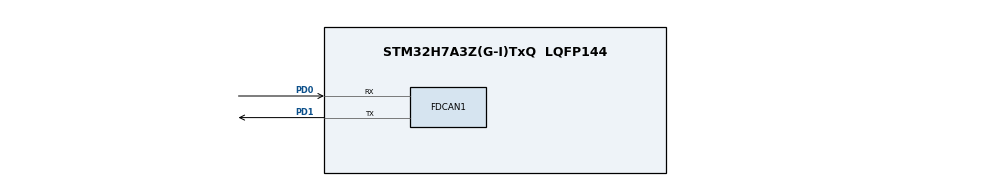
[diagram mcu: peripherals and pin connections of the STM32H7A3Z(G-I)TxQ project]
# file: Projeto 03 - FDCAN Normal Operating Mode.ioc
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FDCAN1.AutoRetransmission=ENABLE
FDCAN1.DataPrescaler=2
FDCAN1.DataSyncJumpWidth=12
FDCAN1.DataTimeSeg1=12
FDCAN1.DataTimeSeg2=12
FDCAN1.FrameFormat=FDCAN_FRAME_FD_BRS
FDCAN1.NominalSyncJumpWidth=13
FDCAN1.NominalTimeSeg1=86
FDCAN1.NominalTimeSeg2=13
FDCAN1.RxBufferSize=FDCAN_DATA_BYTES_12
FDCAN1.RxBuffersNbr=1
FDCAN1.StdFiltersNbr=1
FDCAN1.TxBuffersNbr=1
FDCAN1.TxElmtSize=FDCAN_DATA_BYTES_12
Mcu.Family=STM32H7
Mcu.Name=STM32H7A3Z(G-I)TxQ
Mcu.Package=LQFP144
NVIC.PriorityGroup=NVIC_PRIORITYGROUP_4
PD0.Mode=FDCAN_Activate
PD0.Signal=FDCAN1_RX
PD1.Mode=FDCAN_Activate
PD1.Signal=FDCAN1_TX
ProjectManager.HeapSize=0x200
ProjectManager.StackSize=0x400
ProjectManager.TargetToolchain=STM32CubeIDE
RCC.ADCFreq_Value=129000000
RCC.APB1Freq_Value=75000000
RCC.APB2Freq_Value=75000000
RCC.APB3Freq_Value=75000000
RCC.APB4Freq_Value=75000000
RCC.CortexFreq_Value=75000000
RCC.DIVM1=4
RCC.DIVM3=1
RCC.DIVN1=9
RCC.DIVN3=24
RCC.DIVQ1=3
RCC.HCLKFreq_Value=75000000
RCC.HSE_VALUE=8000000
RCC.PLLFRACN=3072
RCC.PWR_Regulator_Voltage_Scale=PWR_REGULATOR_VOLTAGE_SCALE0
RCC.SYSCLKFreq_VALUE=75000000
RCC.SYSCLKSource=RCC_SYSCLKSOURCE_PLLCLK
RCC.SupplySource=PWR_DIRECT_SMPS_SUPPLY
RCC.USBCLockSelection=RCC_USBCLKSOURCE_HSI48
RCC.USBFreq_Value=48000000
board=NUCLEO-H7A3ZI-Q

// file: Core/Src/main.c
/* USER CODE BEGIN Header */
/**
  ******************************************************************************
  * @file           : main.c
  * @brief          : Main program body
  ******************************************************************************
  * @attention
  *
  * Copyright (c) 2023 STMicroelectronics.
  * All rights reserved.
  *
  * This software is licensed under terms that can be found in the LICENSE file
  * in the root directory of this software component.
  * If no LICENSE file comes with this software, it is provided AS-IS.
  *
  ******************************************************************************
  */
/* USER CODE END Header */
#include "main.h"

FDCAN_HandleTypeDef hfdcan1;

/* USER CODE BEGIN PV */

FDCAN_FilterTypeDef sFilterConfig;
FDCAN_TxHeaderTypeDef TxHeader;
FDCAN_RxHeaderTypeDef RxHeader;
uint8_t TxData_Node1_To_Node2[] = {0x10, 0x13, 0x54, 0x76, 0x98, 0x00, 0x11, 0x22, 0x33, 0x44, 0x55, 0x66};
uint8_t RxData_From_Node2[12];

/* USER CODE END PV */

void SystemClock_Config(void);
static void MX_GPIO_Init(void);
static void MX_FDCAN1_Init(void);

int main(void)
{

  /* MCU Configuration--------------------------------------------------------*/

  /* Reset of all peripherals, Initializes the Flash interface and the Systick. */
  HAL_Init();

  /* Configure the system clock */
  SystemClock_Config();

  /* Initialize all configured peripherals */
  MX_GPIO_Init();
  MX_FDCAN1_Init();
  /* USER CODE BEGIN 2 */

  /* Configure Tx buffer message */
  TxHeader.Identifier = 0x1;
  TxHeader.IdType = FDCAN_STANDARD_ID;
  TxHeader.TxFrameType = FDCAN_DATA_FRAME;
  TxHeader.DataLength = FDCAN_DLC_BYTES_12;
  TxHeader.ErrorStateIndicator = FDCAN_ESI_ACTIVE;
  TxHeader.BitRateSwitch = FDCAN_BRS_ON;
  TxHeader.FDFormat = FDCAN_FD_CAN;
  TxHeader.TxEventFifoControl = FDCAN_NO_TX_EVENTS;
  TxHeader.MessageMarker = 0x0; // Ignore because FDCAN_NO_TX_EVENTS
  if (HAL_FDCAN_AddMessageToTxBuffer(&hfdcan1, &TxHeader, TxData_Node1_To_Node2, FDCAN_TX_BUFFER0) != HAL_OK)
  {
	  Error_Handler();
  }

  /* Configure standard ID reception filter to Rx buffer 0 */
  sFilterConfig.IdType = FDCAN_STANDARD_ID;
  sFilterConfig.FilterType = 0;
#if 0
  sFilterConfig.FilterType = FDCAN_FILTER_DUAL; // Ignore because FDCAN_FILTER_TO_RXBUFFER
#endif
  sFilterConfig.FilterConfig = FDCAN_FILTER_TO_RXBUFFER;
  sFilterConfig.FilterID1 = 0x2; // ID Node2
#if 0
  sFilterConfig.FilterID2 = 0x0; // Ignore because FDCAN_FILTER_TO_RXBUFFER
#endif
  sFilterConfig.RxBufferIndex = 0;
  if (HAL_FDCAN_ConfigFilter(&hfdcan1, &sFilterConfig) != HAL_OK)
  {
	  Error_Handler();
  }

  /* Start the FDCAN module */
  if (HAL_FDCAN_Start(&hfdcan1) != HAL_OK)
  {
	  Error_Handler();
  }

  /* Send Tx buffer message */
  if (HAL_FDCAN_EnableTxBufferRequest(&hfdcan1, FDCAN_TX_BUFFER0) != HAL_OK)
  {
	  Error_Handler();
  }

  /* Polling for transmission complete on buffer index 0 */
  while (HAL_FDCAN_IsTxBufferMessagePending(&hfdcan1, FDCAN_TX_BUFFER0) == 1)

  /* Polling for reception complete on buffer index 0 */
  while (HAL_FDCAN_IsRxBufferMessageAvailable(&hfdcan1, FDCAN_RX_BUFFER0) == 0)

  /* Retrieve message from Rx buffer 0. Rec msg from Node 2 */
  if (HAL_FDCAN_GetRxMessage(&hfdcan1, FDCAN_RX_BUFFER0, &RxHeader, RxData_From_Node2) != HAL_OK)
  {
	  Error_Handler();
  }

  /* USER CODE END 2 */

  /* Infinite loop */
  while (1)
  {

  }
}

void SystemClock_Config(void)
{
  RCC_OscInitTypeDef RCC_OscInitStruct = {0};
  RCC_ClkInitTypeDef RCC_ClkInitStruct = {0};

  /** Supply configuration update enable
  */
  HAL_PWREx_ConfigSupply(PWR_DIRECT_SMPS_SUPPLY);

  /** Configure the main internal regulator output voltage
  */
  __HAL_PWR_VOLTAGESCALING_CONFIG(PWR_REGULATOR_VOLTAGE_SCALE0);

  while(!__HAL_PWR_GET_FLAG(PWR_FLAG_VOSRDY)) {}

  /** Initializes the RCC Oscillators according to the specified parameters
  * in the RCC_OscInitTypeDef structure.
  */
  RCC_OscInitStruct.OscillatorType = RCC_OSCILLATORTYPE_HSI;
  RCC_OscInitStruct.HSIState = RCC_HSI_DIV1;
  RCC_OscInitStruct.HSICalibrationValue = RCC_HSICALIBRATION_DEFAULT;
  RCC_OscInitStruct.PLL.PLLState = RCC_PLL_ON;
  RCC_OscInitStruct.PLL.PLLSource = RCC_PLLSOURCE_HSI;
  RCC_OscInitStruct.PLL.PLLM = 4;
  RCC_OscInitStruct.PLL.PLLN = 9;
  RCC_OscInitStruct.PLL.PLLP = 2;
  RCC_OscInitStruct.PLL.PLLQ = 3;
  RCC_OscInitStruct.PLL.PLLR = 2;
  RCC_OscInitStruct.PLL.PLLRGE = RCC_PLL1VCIRANGE_3;
  RCC_OscInitStruct.PLL.PLLVCOSEL = RCC_PLL1VCOWIDE;
  RCC_OscInitStruct.PLL.PLLFRACN = 3072;
  if (HAL_RCC_OscConfig(&RCC_OscInitStruct) != HAL_OK)
  {
    Error_Handler();
  }

  /** Initializes the CPU, AHB and APB buses clocks
  */
  RCC_ClkInitStruct.ClockType = RCC_CLOCKTYPE_HCLK|RCC_CLOCKTYPE_SYSCLK
                              |RCC_CLOCKTYPE_PCLK1|RCC_CLOCKTYPE_PCLK2
                              |RCC_CLOCKTYPE_D3PCLK1|RCC_CLOCKTYPE_D1PCLK1;
  RCC_ClkInitStruct.SYSCLKSource = RCC_SYSCLKSOURCE_PLLCLK;
  RCC_ClkInitStruct.SYSCLKDivider = RCC_SYSCLK_DIV1;
  RCC_ClkInitStruct.AHBCLKDivider = RCC_HCLK_DIV1;
  RCC_ClkInitStruct.APB3CLKDivider = RCC_APB3_DIV1;
  RCC_ClkInitStruct.APB1CLKDivider = RCC_APB1_DIV1;
  RCC_ClkInitStruct.APB2CLKDivider = RCC_APB2_DIV1;
  RCC_ClkInitStruct.APB4CLKDivider = RCC_APB4_DIV1;

  if (HAL_RCC_ClockConfig(&RCC_ClkInitStruct, FLASH_LATENCY_1) != HAL_OK)
  {
    Error_Handler();
  }
}

static void MX_FDCAN1_Init(void)
{

  hfdcan1.Instance = FDCAN1;
  hfdcan1.Init.FrameFormat = FDCAN_FRAME_FD_BRS;
  hfdcan1.Init.Mode = FDCAN_MODE_NORMAL;
  hfdcan1.Init.AutoRetransmission = ENABLE;
  hfdcan1.Init.TransmitPause = DISABLE;
  hfdcan1.Init.ProtocolException = DISABLE;
  hfdcan1.Init.NominalPrescaler = 1;
  hfdcan1.Init.NominalSyncJumpWidth = 13;
  hfdcan1.Init.NominalTimeSeg1 = 86;
  hfdcan1.Init.NominalTimeSeg2 = 13;
  hfdcan1.Init.DataPrescaler = 2;
  hfdcan1.Init.DataSyncJumpWidth = 12;
  hfdcan1.Init.DataTimeSeg1 = 12;
  hfdcan1.Init.DataTimeSeg2 = 12;
  hfdcan1.Init.MessageRAMOffset = 0;
  hfdcan1.Init.StdFiltersNbr = 1;
  hfdcan1.Init.ExtFiltersNbr = 0;
  hfdcan1.Init.RxFifo0ElmtsNbr = 0;
  hfdcan1.Init.RxFifo0ElmtSize = FDCAN_DATA_BYTES_8;
  hfdcan1.Init.RxFifo1ElmtsNbr = 0;
  hfdcan1.Init.RxFifo1ElmtSize = FDCAN_DATA_BYTES_8;
  hfdcan1.Init.RxBuffersNbr = 1;
  hfdcan1.Init.RxBufferSize = FDCAN_DATA_BYTES_12;
  hfdcan1.Init.TxEventsNbr = 0;
  hfdcan1.Init.TxBuffersNbr = 1;
  hfdcan1.Init.TxFifoQueueElmtsNbr = 0;
  hfdcan1.Init.TxFifoQueueMode = FDCAN_TX_FIFO_OPERATION;
  hfdcan1.Init.TxElmtSize = FDCAN_DATA_BYTES_12;
  if (HAL_FDCAN_Init(&hfdcan1) != HAL_OK)
  {
    Error_Handler();
  }

}

static void MX_GPIO_Init(void)
{

  /* GPIO Ports Clock Enable */
  __HAL_RCC_GPIOD_CLK_ENABLE();

}

void Error_Handler(void)
{
  __disable_irq();
  while (1)
  {
  }
}
